# ADuCM355 register map
Vendor: Analog Devices; Series: ADuCM355; File version: 1p0
CPU: CM3 r0p1, little endian, no MPU, no FPU, 3 interrupt priority bits
Registers are 32-bit, read-write, reset 0x0 unless marked. A register's access mark holds for its fields unless they carry their own. Offsets are from the block's base; [hi:lo] are bit positions.

## UART0
Base 0x40005000
0x00 COMRX 16-bit — Receive Buffer Register
  [7:0] RBR ro
0x00 COMTX 16-bit (alternate view of COMRX) — Transmit Holding Register
  [7:0] THR wo range 0x00000000..0x000000FF
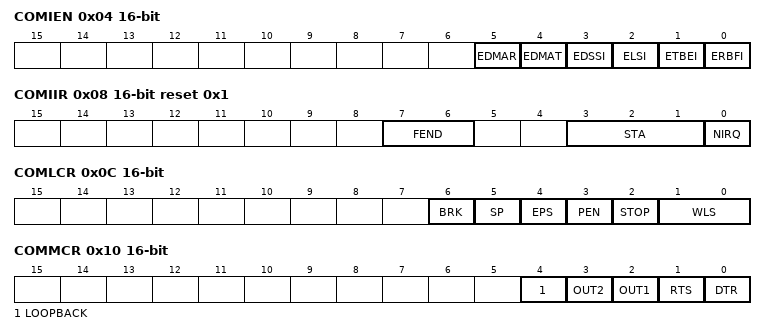
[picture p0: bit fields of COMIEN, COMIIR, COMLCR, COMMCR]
0x04 COMIEN 16-bit — Interrupt Enable
  [5] EDMAR — DMA requests in receive mode
  [4] EDMAT — DMA requests in transmit mode
  [3] EDSSI — Modem status interrupt
  [2] ELSI — Rx status interrupt
  [1] ETBEI — Transmit buffer empty interrupt
  [0] ERBFI — Receive buffer full interrupt
0x08 COMIIR 16-bit reset 0x1 — Interrupt ID
  [7:6] FEND ro — FIFO enabled
  [3:1] STA ro — Interrupt status
  [0] NIRQ ro — Interrupt flag
0x0C COMLCR 16-bit — Line Control
  [6] BRK — Set Break
  [5] SP — Stick Parity
  [4] EPS — Parity Select
  [3] PEN — Parity Enable
  [2] STOP — Stop Bit
  [1:0] WLS — Word Length Select
0x10 COMMCR 16-bit — Modem Control
  [4] LOOPBACK — Loopback mode
  [3] OUT2 — Output 2
  [2] OUT1 — Output 1
  [1] RTS — Request to send
  [0] DTR — Data Terminal Ready
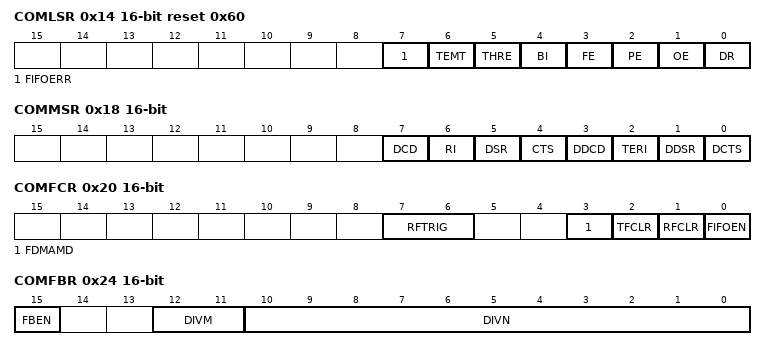
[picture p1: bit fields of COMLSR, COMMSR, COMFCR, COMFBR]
0x14 COMLSR 16-bit reset 0x60 — Line Status
  [7] FIFOERR ro — data byte(s) in RX FIFO have either parity error, frame error or break indication. only used in 16550 mode; Read-clear if no more error in RX FIFO
  [6] TEMT ro — COMTX and Shift Register Empty Status
  [5] THRE ro — COMTX Empty
  [4] BI ro — Break Indicator
  [3] FE ro — Framing Error
  [2] PE ro — Parity Error
  [1] OE ro — Overrun Error
  [0] DR ro — Data Ready
0x18 COMMSR 16-bit — Modem Status
  [7] DCD ro — Data Carrier Detect
  [6] RI ro — Ring Indicator
  [5] DSR ro — Data Set Ready
  [4] CTS ro — Clear To Send
  [3] DDCD ro — Delta DCD
  [2] TERI ro — Trailing Edge RI
  [1] DDSR ro — Delta DSR
  [0] DCTS ro — Delta CTS
0x1C COMSCR 16-bit — Scratch buffer
  [7:0] SCR range 0x00000000..0x000000FF — Scratch
0x20 COMFCR 16-bit — FIFO Control
  [7:6] RFTRIG — RX FIFO Trig level
  [3] FDMAMD — FIFO DMA mode
    0=MODE0 (in DMA mode 0, RX DMA request will be asserted whenever there's data in RBR or RX FIFO and de-assert whenever RBR or RX FIFO is empty; TX DMA request will be asserted whenever THR or TX FIFO is empty and de-assert whenever data written to); 1=MODE1 (in DMA mode 1, RX DMA request will be asserted whenever RX FIFO trig level or time out reached and de-assert thereafter when RX FIFO is empty; TX DMA request will be asserted whenever TX FIFO is empty and de-assert thereafter when TX FIFO is completely filled up full;)
  [2] TFCLR wo range 0x00000000..0x00000001 — clear TX FIFO
  [1] RFCLR wo range 0x00000000..0x00000001 — clear RX FIFO
  [0] FIFOEN range 0x00000000..0x00000001 — FIFO enable as to work in 16550 mode
0x24 COMFBR 16-bit — Fractional Baud Rate
  [15] FBEN range 0x00000000..0x00000001 — Fractional baud rate generator enable
  [12:11] DIVM range 0x00000000..0x00000003 — Fractional baud rate M divide bits 1 to 3
  [10:0] DIVN range 0x00000000..0x000007FF — Fractional baud rate N divide bits 0 to 2047.
0x28 COMDIV 16-bit — Baudrate divider
  [15:0] DIV range 0x00000000..0x0000FFFF — Baud rate divider
0x2C COMLCR2 16-bit reset 0x2 — second Line Control
  [1:0] OSR — Over Sample Rate
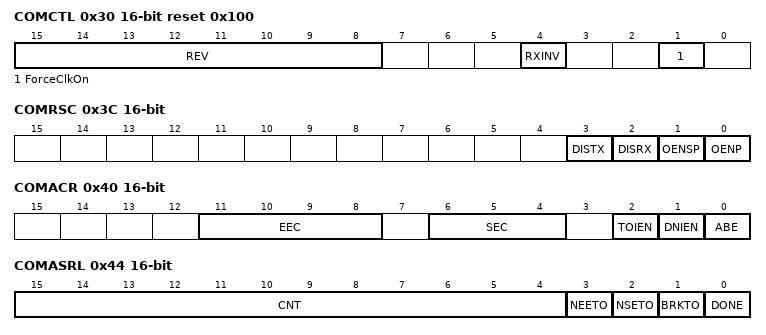
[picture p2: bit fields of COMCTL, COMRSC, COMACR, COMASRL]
0x30 COMCTL 16-bit reset 0x100 — UART control register
  [15:8] REV ro — UART revision ID
  [4] RXINV — invert receiver line
    0=EN000 (don't invert receiver line (idling high)); 1=EN001 (invert receiver line (idling low))
  [1] ForceClkOn — Force UCLKg on
0x34 COMRFC 16-bit — RX FIFO byte count
  [4:0] RFC ro — Current RX FIFO data bytes
0x38 COMTFC 16-bit — TX FIFO byte count
  [4:0] TFC ro — Current TX FIFO data bytes
0x3C COMRSC 16-bit — RS485 half-duplex Control
  [3] DISTX range 0x00000000..0x00000001 — Hold off TX when receiving
  [2] DISRX range 0x00000000..0x00000001 — disable RX when transmitting
  [1] OENSP — SOUT_EN de-assert before full stop bit(s)
  [0] OENP — SOUT_EN polarity
0x40 COMACR 16-bit — Auto Baud Control
  [11:8] EEC — Ending Edge Count
  [6:4] SEC — Starting Edge Count
  [2] TOIEN range 0x00000000..0x00000001 — enable time-out interrupt
  [1] DNIEN range 0x00000000..0x00000001 — enable done interrupt
  [0] ABE range 0x00000000..0x00000001 — Auto Baud enable
0x44 COMASRL 16-bit — Auto Baud Status (Low)
  [15:4] CNT ro — CNT[11:0] Auto Baud Counter value
  [3] NEETO ro — Timed out due to no valid ending edge found
  [2] NSETO ro — Timed out due to no valid start edge found
  [1] BRKTO ro — Timed out due to long time break condition
  [0] DONE ro — Auto Baud Done successfully
0x48 COMASRH 16-bit — Auto Baud Status (High)
  [7:0] CNT ro — CNT[19:12] Auto Baud Counter value
